# MKE14Z7 register map
Vendor: Freescale Semiconductor, Inc.; Series: Kinetis_E; File version: 1.6
CPU: CM0PLUS r0p0, little endian, no MPU, no FPU, VTOR, 2 interrupt priority bits
Registers are 32-bit, read-write, reset 0x0 unless marked. A register's access mark holds for its fields unless they carry their own. Offsets are from the block's base; [hi:lo] are bit positions.

## PMC
Base 0x4007D000; register names take the prefix PMC_
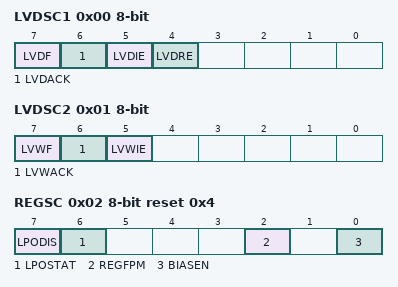
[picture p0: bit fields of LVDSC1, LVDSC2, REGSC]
0x00 LVDSC1 8-bit — Low Voltage Detect Status and Control 1 Register
  [7] LVDF ro — Low Voltage Detect Flag
    0=Low-voltage event not detected; 1=Low-voltage event detected
  [6] LVDACK wo — Low Voltage Detect Acknowledge
  [5] LVDIE — Low Voltage Detect Interrupt Enable
    0=Hardware interrupt disabled (use polling); 1=Request a hardware interrupt when LVDF = 1
  [4] LVDRE — Low Voltage Detect Reset Enable
    0=No system resets on low voltage detect events; 1=If the supply voltage falls below VLVD, a system reset will be generated
0x01 LVDSC2 8-bit — Low Voltage Detect Status and Control 2 Register
  [7] LVWF ro — Low-Voltage Warning Flag
    0=Low-voltage warning event not detected; 1=Low-voltage warning event detected
  [6] LVWACK wo — Low-Voltage Warning Acknowledge
  [5] LVWIE — Low-Voltage Warning Interrupt Enable
    0=Hardware interrupt disabled (use polling); 1=Request a hardware interrupt when LVWF=1
0x02 REGSC 8-bit reset 0x4 — Regulator Status and Control Register
  [7] LPODIS — LPO Disable Bit
    0=Low power oscillator enabled; 1=Low power oscillator disabled
  [6] LPOSTAT ro — LPO Status Bit
    0=Low power oscillator in low phase; 1=Low power oscillator in high phase
  [2] REGFPM ro — Regulator in Full Performance Mode Status Bit
    0=Regulator is in low power mode or transition to/from; 1=Regulator is in full performance mode
  [0] BIASEN — Bias Enable Bit
    0=Biasing disabled, core logic can run in full performance; 1=Biasing enabled, core logic is slower and there are restrictions in allowed system clock speed (see device level specification for details)
0x04 LPOTRIM 8-bit — Low Power Oscillator Trim Register
  [4:0] LPOTRIM — LPO trimming bits

## SMC — System Mode Controller
Base 0x4007E000; register names take the prefix SMC_
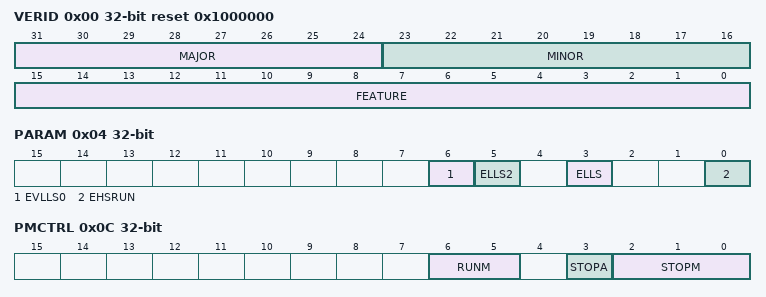
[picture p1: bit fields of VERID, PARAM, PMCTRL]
0x00 VERID ro reset 0x1000000 — SMC Version ID Register
  [31:24] MAJOR — Major Version Number
  [23:16] MINOR — Minor Version Number
  [15:0] FEATURE — Feature Specification Number
    0=Standard features implemented
0x04 PARAM ro — SMC Parameter Register
  [all] fields
    0=The feature is not available; 1=The feature is available
  [6] EVLLS0 — VLLS0 feature exists
  [5] ELLS2 — LLS2 feature exists
  [3] ELLS — LLS feature exists
  [0] EHSRUN — HSRUN feature exists
0x08 PMPROT — Power Mode Protection register
  [5] AVLP — Allow Very-Low-Power Modes
    0=VLPR, VLPW, and VLPS are not allowed; 1=VLPR, VLPW, and VLPS are allowed
0x0C PMCTRL — Power Mode Control register
  [6:5] RUNM — Run Mode Control
    0=Normal Run mode (RUN); 2=Very-Low-Power Run mode (VLPR)
  [3] STOPA ro — Stop Aborted
    0=The previous stop mode entry was successful; 1=The previous stop mode entry was aborted
  [2:0] STOPM — Stop Mode Control
    0=Normal Stop (STOP); 2=Very-Low-Power Stop (VLPS); 6=Reseved
0x10 STOPCTRL reset 0x3 — Stop Control Register
  [7:6] PSTOPO — Partial Stop Option
    0=STOP - Normal Stop mode; 1=PSTOP1 - Partial Stop with both system and bus clocks disabled; 2=PSTOP2 - Partial Stop with system clock disabled and bus clock enabled
0x14 PMSTAT ro reset 0x1 — Power Mode Status register
  [7:0] PMSTAT — Power Mode Status

## GPIOA — General Purpose Input/Output
Base 0x400FF000; register names take the prefix GPIOA_
0x00 PDOR — Port Data Output Register
  [31:0] PDO — Port Data Output
    0=Logic level 0 is driven on pin, provided pin is configured for general-purpose output; 1=Logic level 1 is driven on pin, provided pin is configured for general-purpose output
0x04 PSOR wo — Port Set Output Register
  [31:0] PTSO — Port Set Output
    0=Corresponding bit in PDORn does not change; 1=Corresponding bit in PDORn is set to logic 1
0x08 PCOR wo — Port Clear Output Register
  [31:0] PTCO — Port Clear Output
    0=Corresponding bit in PDORn does not change; 1=Corresponding bit in PDORn is cleared to logic 0
0x0C PTOR wo — Port Toggle Output Register
  [31:0] PTTO — Port Toggle Output
    0=Corresponding bit in PDORn does not change; 1=Corresponding bit in PDORn is set to the inverse of its existing logic state
0x10 PDIR ro — Port Data Input Register
  [31:0] PDI — Port Data Input
    0=Pin logic level is logic 0, or is not configured for use by digital function; 1=Pin logic level is logic 1
0x14 PDDR — Port Data Direction Register
  [31:0] PDD — Port Data Direction
    0=Pin is configured as general-purpose input, for the GPIO function; 1=Pin is configured as general-purpose output, for the GPIO function

## GPIOB — General Purpose Input/Output
Base 0x400FF040; register names take the prefix GPIOB_
Registers as GPIOA.

## GPIOC — General Purpose Input/Output
Base 0x400FF080; register names take the prefix GPIOC_
Registers as GPIOA.

## GPIOD — General Purpose Input/Output
Base 0x400FF0C0; register names take the prefix GPIOD_
Registers as GPIOA.

## GPIOE — General Purpose Input/Output
Base 0x400FF100; register names take the prefix GPIOE_
Registers as GPIOA.
